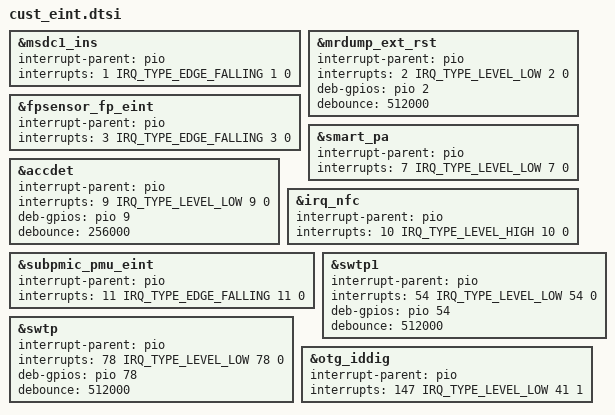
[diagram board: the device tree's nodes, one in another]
/*
 * Generated by MTK SP DrvGen Version: 3.5.160809 for MT6761.
 * 2026-10-24 10:44:15
 * Do Not Modify The File.
 * Copyright Mediatek Inc. (c) 2016.
*/

/*************************
 * EINT DTSI File
*************************/

#include <dt-bindings/interrupt-controller/irq.h>
#include <dt-bindings/interrupt-controller/arm-gic.h>

&msdc1_ins {
	interrupt-parent = <&pio>;
	interrupts = <1 IRQ_TYPE_EDGE_FALLING 1 0>;
	status = "okay";
};

&mrdump_ext_rst {
	interrupt-parent = <&pio>;
	interrupts = <2 IRQ_TYPE_LEVEL_LOW 2 0>;
	deb-gpios = <&pio 2 0>;
	debounce = <512000>;
	status = "okay";
};

&fpsensor_fp_eint {
	interrupt-parent = <&pio>;
	interrupts = <3 IRQ_TYPE_EDGE_FALLING 3 0>;
	status = "okay";
};

&smart_pa {
	interrupt-parent = <&pio>;
	interrupts = <7 IRQ_TYPE_LEVEL_LOW 7 0>;
	status = "okay";
};

&accdet {
	interrupt-parent = <&pio>;
	interrupts = <9 IRQ_TYPE_LEVEL_LOW 9 0>;
	deb-gpios = <&pio 9 0>;
	debounce = <256000>;
	status = "okay";
};

&irq_nfc {
	interrupt-parent = <&pio>;
	interrupts = <10 IRQ_TYPE_LEVEL_HIGH 10 0>;
	status = "okay";
};

&subpmic_pmu_eint {
	interrupt-parent = <&pio>;
	interrupts = <11 IRQ_TYPE_EDGE_FALLING 11 0>;
	status = "okay";
};

&swtp1 {
	interrupt-parent = <&pio>;
	interrupts = <54 IRQ_TYPE_LEVEL_LOW 54 0>;
	deb-gpios = <&pio 54 0>;
	debounce = <512000>;
	status = "okay";
};

&swtp {
	interrupt-parent = <&pio>;
	interrupts = <78 IRQ_TYPE_LEVEL_LOW 78 0>;
	deb-gpios = <&pio 78 0>;
	debounce = <512000>;
	status = "okay";
};

&otg_iddig {
	interrupt-parent = <&pio>;
	interrupts = <147 IRQ_TYPE_LEVEL_LOW 41 1>;
	status = "okay";
};

